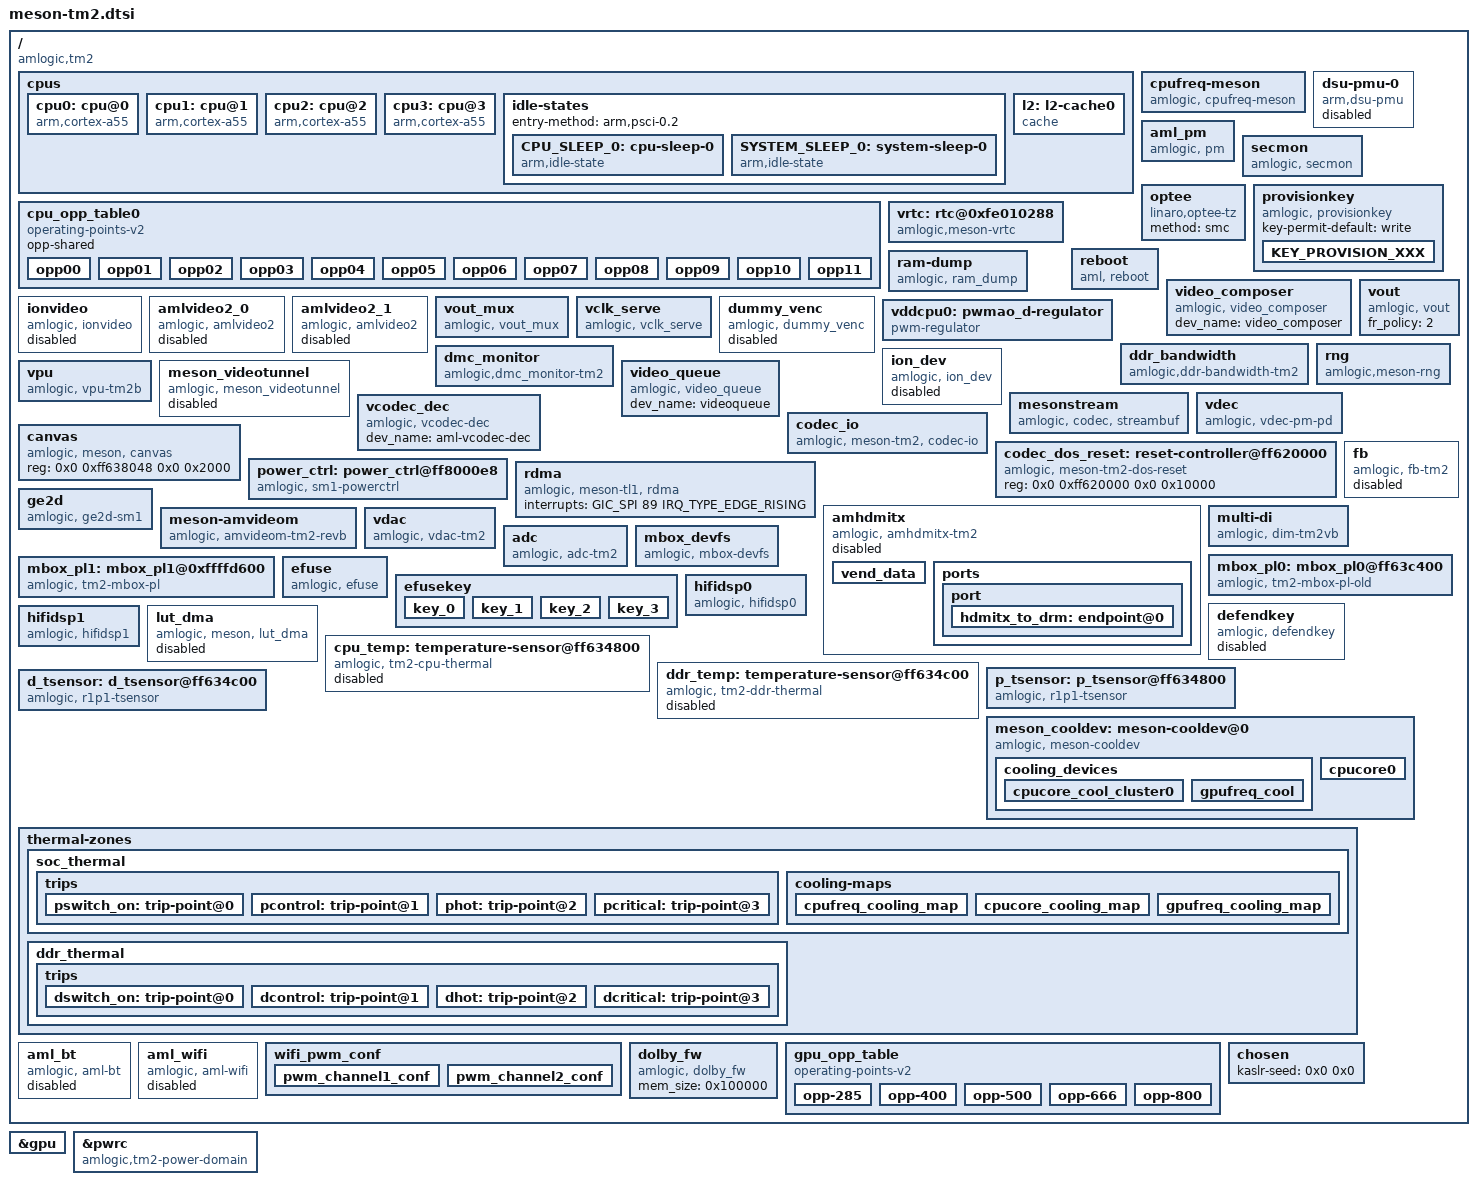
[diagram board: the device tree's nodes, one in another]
// SPDX-License-Identifier: (GPL-2.0+ OR MIT)
/*
 * Copyright (c) 2019 BayLibre, SAS
 * Author: Neil Armstrong <narmstrong@baylibre.com>
 */

#include "meson-tm-common.dtsi"
#include <dt-bindings/clock/tm2-clkc.h>
#include <dt-bindings/power/tm2-pd.h>
#include <dt-bindings/mailbox/tm2-mbox.h>
#include "mesong12a-bifrost.dtsi"
#include <dt-bindings/firmware/amlogic,firmware.h>

/ {
	compatible = "amlogic,tm2";

	cpus {
		#address-cells = <0x2>;
		#size-cells = <0x0>;

		cpu0: cpu@0 {
			device_type = "cpu";
			compatible = "arm,cortex-a55";
			reg = <0x0 0x0>;
			enable-method = "psci";
			//cpu-idle-states = <&CPU_SLEEP_0>;
			next-level-cache = <&l2>;
			clocks = <&clkc CLKID_CPU_CLK>,
				<&clkc CLKID_CPU_CLK_DYN>,
				<&clkc CLKID_SYS_PLL>,
				<&clkc CLKID_DSU_CLK>,
				<&clkc CLKID_DSU_CLK_FINAL>;
			clock-names = "core_clk",
				"low_freq_clk_parent",
				"high_freq_clk_parent",
				"dsu_clk",
				"dsu_pre_parent";
			operating-points-v2 = <&cpu_opp_table0>;
			cpu-supply = <&vddcpu0>;
			voltage-tolerance = <0>;
			clock-latency = <50000>;
			dynamic-power-coefficient = <140>;
			#cooling-cells = <2>;
		};

		cpu1: cpu@1 {
			device_type = "cpu";
			compatible = "arm,cortex-a55";
			reg = <0x0 0x1>;
			enable-method = "psci";
			//cpu-idle-states = <&CPU_SLEEP_0>;
			next-level-cache = <&l2>;
			//clocks = <&clkc CLKID_CPU_CLK>,
			//	<&clkc CLKID_CPU_CLK_DYN>,
			//	<&clkc CLKID_SYS_PLL>,
			//	<&clkc CLKID_DSU_CLK>,
			//	<&clkc CLKID_DSU_CLK_FINAL>;
			//clock-names = "core_clk",
			//	"low_freq_clk_parent",
			//	"high_freq_clk_parent",
			//	"dsu_clk",
			//	"dsu_pre_parent";
			operating-points-v2 = <&cpu_opp_table0>;
			cpu-supply = <&vddcpu0>;
			voltage-tolerance = <0>;
			clock-latency = <50000>;
			dynamic-power-coefficient = <140>;
			#cooling-cells = <2>;
		};

		cpu2: cpu@2 {
			device_type = "cpu";
			compatible = "arm,cortex-a55";
			reg = <0x0 0x2>;
			enable-method = "psci";
			//cpu-idle-states = <&CPU_SLEEP_0>;
			next-level-cache = <&l2>;
			//clocks = <&clkc CLKID_CPU_CLK>,
			//	<&clkc CLKID_CPU_CLK_DYN>,
			//	<&clkc CLKID_SYS_PLL>,
			//	<&clkc CLKID_DSU_CLK>,
			//	<&clkc CLKID_DSU_CLK_FINAL>;
			//clock-names = "core_clk",
			//	"low_freq_clk_parent",
			//	"high_freq_clk_parent",
			//	"dsu_clk",
			//	"dsu_pre_parent";
			operating-points-v2 = <&cpu_opp_table0>;
			cpu-supply = <&vddcpu0>;
			voltage-tolerance = <0>;
			clock-latency = <50000>;
			dynamic-power-coefficient = <140>;
			#cooling-cells = <2>;
		};

		cpu3: cpu@3 {
			device_type = "cpu";
			compatible = "arm,cortex-a55";
			reg = <0x0 0x3>;
			enable-method = "psci";
			//cpu-idle-states = <&CPU_SLEEP_0>;
			next-level-cache = <&l2>;
			//clocks = <&clkc CLKID_CPU_CLK>,
			//	<&clkc CLKID_CPU_CLK_DYN>,
			//	<&clkc CLKID_SYS_PLL>,
			//	<&clkc CLKID_DSU_CLK>,
			//	<&clkc CLKID_DSU_CLK_FINAL>;
			//clock-names = "core_clk",
			//	"low_freq_clk_parent",
			//	"high_freq_clk_parent",
			//	"dsu_clk",
			//	"dsu_pre_parent";
			operating-points-v2 = <&cpu_opp_table0>;
			cpu-supply = <&vddcpu0>;
			voltage-tolerance = <0>;
			clock-latency = <50000>;
			dynamic-power-coefficient = <140>;
			#cooling-cells = <2>;
		};

		idle-states {
			entry-method = "arm,psci-0.2";
			CPU_SLEEP_0: cpu-sleep-0 {
				compatible = "arm,idle-state";
				arm,psci-suspend-param = <0x0010000>;
				local-timer-stop;
				entry-latency-us = <4000>;
				exit-latency-us = <5000>;
				min-residency-us = <10000>;
			};
			SYSTEM_SLEEP_0: system-sleep-0 {
					compatible = "arm,idle-state";
					arm,psci-suspend-param = <0x0000000>;
					entry-latency-us = <0x3fffffff>;
					exit-latency-us = <0x40000000>;
					min-residency-us = <0xffffffff>;
			};
		};

		l2: l2-cache0 {
			compatible = "cache";
		};
	};

	cpu_opp_table0: cpu_opp_table0 {
		compatible = "operating-points-v2";
		opp-shared;

		opp00 {
			opp-hz = /bits/ 64 <100000000>;
			opp-microvolt = <780000>;
		};
		opp01 {
			opp-hz = /bits/ 64 <250000000>;
			opp-microvolt = <780000>;
		};
		opp02 {
			opp-hz = /bits/ 64 <500000000>;
			opp-microvolt = <780000>;
		};
		opp03 {
			opp-hz = /bits/ 64 <667000000>;
			opp-microvolt = <780000>;
		};
		opp04 {
			opp-hz = /bits/ 64 <1000000000>;
			opp-microvolt = <780000>;
		};
		opp05 {
			opp-hz = /bits/ 64 <1200000000>;
			opp-microvolt = <800000>;
		};
		opp06 {
			opp-hz = /bits/ 64 <1404000000>;
			opp-microvolt = <810000>;
		};
		opp07 {
			opp-hz = /bits/ 64 <1500000000>;
			opp-microvolt = <820000>;
		};
		opp08 {
			opp-hz = /bits/ 64 <1608000000>;
			opp-microvolt = <870000>;
		};
		opp09 {
			opp-hz = /bits/ 64 <1704000000>;
			opp-microvolt = <920000>;
		};
		opp10 {
			opp-hz = /bits/ 64 <1800000000>;
			opp-microvolt = <970000>;
		};
		opp11 {
			opp-hz = /bits/ 64 <1908000000>;
			opp-microvolt = <1020000>;
		};
	};

	cpufreq-meson {
		compatible = "amlogic, cpufreq-meson";
		pinctrl-names = "default";
		//pinctrl-0 = <&pwm_ao_d_pins3>;
		status = "okay";
	};

	dsu-pmu-0 {
	compatible = "arm,dsu-pmu";
		status = "disabled";
		cpus = <&cpu0>,<&cpu1>,<&cpu2>,<&cpu3>;
		interrupts = <GIC_SPI 134 IRQ_TYPE_LEVEL_HIGH>;
	};

	aml_pm {
		compatible = "amlogic, pm";
		status = "okay";
		device_name = "aml_pm";
		reg = <0x0 0xff8000a8 0x0 0x4>, /*SYSCTRL_STATUS_REG2*/
			<0x0 0xff80023c 0x0 0x4>; /*SYSCTRL_SEC_STATUS_REG31*/
	};

	secmon {
		compatible = "amlogic, secmon";
		memory-region = <&secmon_reserved>;
		in_base_func = <0x82000020>;
		out_base_func = <0x82000021>;
		inout_size_func = <0x8200002a>;
		reserve_mem_size = <0x00300000>;
	};

	optee {
		compatible = "linaro,optee-tz";
		method = "smc";
	};

	provisionkey {
		compatible = "amlogic, provisionkey";
		status = "okay";
		key-permit-default = "write";
		//new key not need add dts if started with KEY_PROVISION_
		KEY_PROVISION_XXX { };
		//test_my_added_keyname { };
	};//End provisionkey

	vrtc: rtc@0xfe010288 {
		compatible = "amlogic,meson-vrtc";
		reg = <0x0 0xff8000a8 0x0 0x4>;	/*AO_DEBUG_REG2*/
		status = "okay";
		mboxes = <&mbox_pl0 TM2_REE2AO_VRTC>;
	};

	reboot {
		compatible = "aml, reboot";
		sys_reset = <0x84000009>;
		sys_poweroff = <0x84000008>;
		reg = <0x0 0xff80023c 0x0 0x4>; /* SEC_AO_SEC_SD_CFG15 */
		status = "okay";
	};

	ram-dump {
		compatible = "amlogic, ram_dump";
		status = "okay";
		reg = <0x0 0xFF6345E0 0x0 4>;
		reg-names = "SYSCTRL_STICKY_REG6";
		store_device = "data";
	};

	video_composer {
		compatible = "amlogic, video_composer";
		dev_name = "video_composer";
		status = "disabled";
	};

	ionvideo {
		compatible = "amlogic, ionvideo";
		status = "disabled";
	};

	amlvideo2_0 {
		compatible = "amlogic, amlvideo2";
		dev_name = "amlvideo2";
		status = "disabled";
		amlvideo2_id = <0>;
		cma_mode = <1>;
	};

	amlvideo2_1 {
		compatible = "amlogic, amlvideo2";
		dev_name = "amlvideo2";
		status = "disabled";
		amlvideo2_id = <1>;
		cma_mode = <1>;
	};

	vout: vout {
		compatible = "amlogic, vout";
		status = "okay";

		/* fr_policy:
		 *    0: disable
		 *    1: nearby (only for 60->59.94 and 30->29.97)
		 *    2: force (60/50/30/24/59.94/23.97)
		 */
		fr_policy = <2>;
	};

	vout_mux: vout_mux {
		compatible = "amlogic, vout_mux";
		status = "okay";
	};

	vclk_serve: vclk_serve {
		compatible = "amlogic, vclk_serve";
		status = "okay";
		reg = <0x0 0xff63c000 0x0 0x4a0    /* ana reg */
				0x0 0xff63c000 0x0 0x4a0>;    /* clk reg */
	};

	dummy_venc: dummy_venc {
		compatible = "amlogic, dummy_venc";
		status = "disabled";
		clocks = <&clkc CLKID_VCLK2_ENCP
			&clkc CLKID_VCLK2_VENCP0
			&clkc CLKID_VCLK2_VENCP1
			&clkc CLKID_VCLK2_ENCI
			&clkc CLKID_VCLK2_VENCI0
			&clkc CLKID_VCLK2_VENCI1
			&clkc CLKID_VCLK2_ENCL
			&clkc CLKID_VCLK2_VENCL>;
		clock-names = "encp_top_gate",
			"encp_int_gate0",
			"encp_int_gate1",
			"venci_top_gate",
			"enci_int_gate0",
			"enci_int_gate1",
			"encl_top_gate",
			"encl_int_gate";
	};

	vddcpu0: pwmao_d-regulator {
		compatible = "pwm-regulator";
		pwms = <&pwm_AO_cd MESON_PWM_1 1500 0>;
		regulator-name = "vddcpu0";
		regulator-min-microvolt = <690000>;
		regulator-max-microvolt = <1050000>;
		regulator-always-on;
		max-duty-cycle = <1500>;
		/* Voltage Duty-Cycle */
		voltage-table = <1050000 0>,
			<1040000 3>,
			<1030000 6>,
			<1020000 9>,
			<1010000 12>,
			<1000000 14>,
			<990000 17>,
			<980000 20>,
			<970000 23>,
			<960000 26>,
			<950000 29>,
			<940000 31>,
			<930000 34>,
			<920000 37>,
			<910000 40>,
			<900000 43>,
			<890000 45>,
			<880000 48>,
			<870000 51>,
			<860000 54>,
			<850000 56>,
			<840000 59>,
			<830000 62>,
			<820000 65>,
			<810000 68>,
			<800000 70>,
			<790000 73>,
			<780000 76>,
			<770000 79>,
			<760000 81>,
			<750000 84>,
			<740000 87>,
			<730000 89>,
			<720000 92>,
			<710000 95>,
			<700000 98>,
			<690000 100>;
		status = "okay";
	};

	ddr_bandwidth {
		compatible = "amlogic,ddr-bandwidth-tm2";
		status = "okay";
		reg = <0x0 0xff638000 0x0 0x100
		       0x0 0xff638c00 0x0 0x100>;
		interrupts = <GIC_SPI 52 IRQ_TYPE_LEVEL_HIGH>;
		interrupt-names = "ddr_bandwidth";
	};

	dmc_monitor {
		compatible = "amlogic,dmc_monitor-tm2";
		status = "okay";
		reg = <0x0 0xff638000 0x0 0x100>;
		reg_base = <0xff639000>;
		interrupts = <GIC_SPI 52 IRQ_TYPE_LEVEL_HIGH>;
	};

	rng {
		compatible = "amlogic,meson-rng";
		status = "okay";
		#address-cells = <2>;
		#size-cells = <2>;
		reg = <0x0 0xff630218 0x0 0x4>;
		quality = /bits/ 16 <1000>;
	};

	ion_dev: ion_dev {
		status = "disabled";
		compatible = "amlogic, ion_dev";
		memory-region = <&ion_cma_reserved
				&ion_fb_reserved>;
	};

	vpu: vpu {
		compatible = "amlogic, vpu-tm2b";
		status = "okay";
		reg =	<0x0 0xff63c000 0x0 0x200  /* hiu */
			0x0 0xff900000 0x0 0x50000 /* vcbus */
			0x0 0xffd00000 0x0 0x10a0  /* cbus */
			0x0 0xff800000 0x0 0x100>; /* aobus */
		clocks = <&clkc CLKID_VAPB_SEL>,
			<&clkc CLKID_VPU_INTR>,
			<&clkc CLKID_VPU_0>,
			<&clkc CLKID_VPU_1>,
			<&clkc CLKID_VPU>;
		clock-names =	"vapb_clk",
				"vpu_intr_gate",
				"vpu_clk0",
				"vpu_clk1",
				"vpu_clk";
		clk_level = <8>;
		/* 0: 24M       1: 100.0M    2: 166.7M    3: 200.0M    4: 250.0M */
		/* 5: 333.3M    6: 400.0M    7: 500.0M    8: 666.7M */
	};

	meson_videotunnel{
		compatible = "amlogic, meson_videotunnel";
		status = "disabled";
	};

	video_composer {
		compatible = "amlogic, video_composer";
		dev_name = "video_composer";
		status = "okay";
	};

	video_queue {
		compatible = "amlogic, video_queue";
		dev_name = "videoqueue";
		status = "okay";
	};

	mesonstream {
		compatible = "amlogic, codec, streambuf";
		dev_name = "mesonstream";
		status = "okay";
		clocks = <&clkc CLKID_U_PARSER
			&clkc CLKID_DEMUX
			&clkc CLKID_AHB_ARB0
			&clkc CLKID_DOS
			&clkc CLKID_CLK81
			&clkc CLKID_VDEC_MUX
			&clkc CLKID_HCODEC_MUX
			&clkc CLKID_HEVC_MUX
			&clkc CLKID_HEVCF_MUX>;
		clock-names = "parser_top",
			"demux",
			"ahbarb0",
			"vdec",
			"clk_81",
			"clk_vdec_mux",
			"clk_hcodec_mux",
			"clk_hevc_mux",
			"clk_hevcb_mux";
	};

	vdec {
		compatible = "amlogic, vdec-pm-pd";
		dev_name = "vdec.0";
		status = "okay";
		interrupts = <0 3 1
			0 23 1
			0 32 1
			0 43 1
			0 44 1
			0 45 1
			0 74 1>;
		interrupt-names = "vsync",
			"demux",
			"parser",
			"mailbox_0",
			"mailbox_1",
			"mailbox_2",
			"parser_b";
		power-domains = <&pwrc PWRC_TM2_VDEC_ID>,
			<&pwrc PWRC_TM2_HCODEC_ID>,
			<&pwrc PWRC_TM2_HEVC_ID>;
		power-domain-names = "pwrc-vdec",
			"pwrc-hcodec",
			"pwrc-hevc";
	};

	vcodec_dec {
		compatible = "amlogic, vcodec-dec";
		dev_name = "aml-vcodec-dec";
		status = "okay";
	};

	canvas: canvas {
		compatible = "amlogic, meson, canvas";
		status = "okay";
		reg = <0x0 0xff638048 0x0 0x2000>;
	};

	codec_io: codec_io {
		compatible = "amlogic, meson-tm2, codec-io";
		status = "okay";
		#address-cells=<2>;
		#size-cells=<2>;
		ranges;
		reg =	<0x0 0xffd00000 0x0 0x100000>,
			<0x0 0xff620000 0x0 0x10000>,
			<0x0 0xff63c000 0x0 0x2000>,
			<0x0 0xff800000 0x0 0x10000>,
			<0x0 0xff900000 0x0 0x40000>,
			<0x0 0xff638000 0x0 0x2000>,
			<0x0 0xff630000 0x0 0x2000>;
		reg-names = "cbus",
			    "dosbus",
			    "hiubus",
			    "aobus",
			    "vcbus",
			    "dmcbus",
			    "efusebus";
	};

	codec_dos_reset: reset-controller@ff620000 {
		compatible = "amlogic, meson-tm2-dos-reset";
		status = "okay";
		reg = <0x0 0xff620000 0x0 0x10000>;
		#reset-cells = <1>;
	};

	power_ctrl: power_ctrl@ff8000e8 {
		compatible = "amlogic, sm1-powerctrl";
		reg = <0x0 0xff8000e8 0x0 0x10>,
		<0x0 0xff63c100 0x0 0x10>;
	};

	rdma {
		compatible = "amlogic, meson-tl1, rdma";
		status = "okay";
		interrupts = <GIC_SPI 89 IRQ_TYPE_EDGE_RISING>;
		interrupt-names = "rdma";
	};

	fb: fb {
		compatible = "amlogic, fb-tm2";
		memory-region = <&logo_reserved>;
		status = "disabled";
		interrupts = <GIC_SPI 3 IRQ_TYPE_EDGE_RISING
			GIC_SPI 56 IRQ_TYPE_EDGE_RISING
			GIC_SPI 89 IRQ_TYPE_EDGE_RISING>;
		interrupt-names = "viu-vsync", "viu2-vsync", "rdma";
		/* uboot logo,fb0/fb1 memory size,if afbcd fb0=0x01851000*/
		display_mode_default = "1080p60hz";
		scale_mode = <1>;
		/** 0:VPU free scale 1:OSD free scale 2:OSD super scale */
		display_size_default = <1920 1080 1920 2160 32>;
		/*1920*1080*4*3 = 0x17BB000*/
		clocks = <&clkc CLKID_VPU_CLKC_MUX>;
		clock-names = "vpu_clkc";
	};

	amhdmitx: amhdmitx{
		compatible = "amlogic, amhdmitx-tm2";
		dev_name = "amhdmitx";
		status = "disabled";
		vend-data = <&vend_data>;
		pinctrl-names="default", "hdmitx_i2c";
		pinctrl-0=<&hdmitx_hpd &hdmitx_ddc>;
		pinctrl-1=<&hdmitx_hpd_gpio>;
		hdmitx-gpios-hpd = <&gpio GPIOH_16 0>;
		hdmitx-gpios-scl = <&gpio GPIOH_23 0>;
		hdmitx-gpios-sda = <&gpio GPIOH_24 0>;
		clocks = <&clkc CLKID_VCLK2_ENCI
			&clkc CLKID_VCLK2_VENCI0
			&clkc CLKID_VCLK2_VENCI1
			&clkc CLKID_VAPB_SEL
			&clkc CLKID_VPU
			&clkc CLKID_HDMIRX_AXI_GATE>;
		clock-names = "venci_top_gate",
			"venci_0_gate",
			"venci_1_gate",
			"hdmi_vapb_clk",
			"hdmi_vpu_clk",
			"cts_hdmi_axi_clk";
		interrupts = <0 7 IRQ_TYPE_LEVEL_HIGH
			0 3 IRQ_TYPE_EDGE_RISING>;
		interrupt-names = "hdmitx_hpd", "viu1_vsync";
		/* HPD, 57 + 32 = 89; CEC, 151 + 32 = 183*/
		/* 0:M8B   1:GXBB 2:GXTVBB 3:GXL  4:GXM
		 * 5:TXL   6:TXLX 7:AXG    8:GXLX 9:TXHD
		 * 10:G12A 11:G12B 12:SM1  13:TM2
		 */
		ic_type = <13>;
		reg =	<0x0 0xffd00000 0x0 0x100000>,
			<0x0 0xff900000 0x0 0x40000>,
			<0x0 0xff63c000 0x0 0x2000>,
			<0x0 0xff678000 0x0 0x8000>,
			<0x0 0xff670000 0x0 0x8000>,
			<0x0 0xffe01000 0x0 0x1000>;
		reg-names = "cbus",
			    "vcbus",
			    "hiubus",
			    "hdmitx_sec",
			    "hdmitx",
			    "esm";
		vend_data: vend_data{ /* Should modified by Customer */
			vendor_name = "Amlogic"; /* Max Chars: 8 */
			product_desc = "MBox Meson Ref"; /* Max Chars: 16 */
			/* standards.ieee.org/develop/regauth/oui/oui.txt */
			vendor_id = <0x000000>;
		};

		ports {
			port {
				#address-cells = <1>;
				#size-cells = <0>;
				hdmitx_to_drm: endpoint@0 {
					reg = <0>;
					remote-endpoint = <0>;
				};
			};
		};
	};

	ge2d {
		compatible = "amlogic, ge2d-sm1";
		status = "okay";
		interrupts = <GIC_SPI 146 IRQ_TYPE_EDGE_RISING>;
		interrupt-names = "ge2d";
		clocks = <&clkc CLKID_VAPB_SEL>,
			<&clkc CLKID_G2D>,
			<&clkc CLKID_VAPB>;
		clock-names = "clk_vapb_0",
			"clk_ge2d",
			"clk_ge2d_gate";
		reg = <0x0 0xff940000 0x0 0x10000>;
		power-domains = <&pwrc PWRC_TM2_GE2D_ID>;
		power-domain-names = "ge2d";
	};

	multi-di {
		compatible = "amlogic, dim-tm2vb";
		status = "okay";
		/* 0:use reserved; 1:use cma; 2:use cma as reserved */
		flag_cma = <4>;
		//memory-region = <&di_reserved>;
		memory-region = <&di_cma_reserved>;
		interrupts = <0 46 1
				0 40 1>;
		interrupt-names = "pre_irq", "post_irq";
		clocks = <&clkc CLKID_VPU_CLKB
			&clkc CLKID_VPU>;
		clock-names = "vpu_clkb",
			"vpu_mux";
		clock-range = <334 667>;
		/* buffer-size = <3621952>;(yuv422 8bit) */
		buffer-size = <4074560>;/*yuv422 fullpack*/
		/* reserve-iomap = "true"; */
		/* if enable nr10bit, set nr10bit-support to 1 */
		post-wr-support = <1>;
		nr10bit-support = <1>;
		nrds-enable = <1>;
		pps-enable = <1>;
	};

	meson-amvideom {
		compatible = "amlogic, amvideom-tm2-revb";
		dev_name = "amvideom";
		status = "okay";
		interrupts = <0 3 1>;
		interrupt-names = "vsync";
	};

	vdac: vdac {
		compatible = "amlogic, vdac-tm2";
		status = "okay";
	};

	adc: adc {
		compatible = "amlogic, adc-tm2";
		status = "okay";
		reg = <0x0 0xff654000 0x0 0x2000/* afe reg base */
			0x0 0xff63c000 0x0 0x2000/* hiu base */
			>;
	};

	mbox_pl0: mbox_pl0@ff63c400 {
		status = "okay";
		compatible = "amlogic, tm2-mbox-pl-old";
		reg = <0x0 0xfffdf200 0x0 0x200>,   // aocpu tx buf low
		      <0x0 0xfffdf000 0x0 0x200>,   // aocpu rx buf low
		      <0x0 0xff63c434 0x0 0x4>,     // aocpu tx set addr low
		      <0x0 0xff63c418 0x0 0x4>,     // aocpu rx clr addr low
		      <0x0 0xff63c414 0x0 0x4>,     // aocpu rx sts addr low
		      <0x0 0xfffdf600 0x0 0x200>,   // aocpu tx buf high
		      <0x0 0xfffdf400 0x0 0x200>,   // aocpu rx buf high
		      <0x0 0xff63c440 0x0 0x4>,     // aocpu tx set addr high
		      <0x0 0xff63c424 0x0 0x4>,     // aocpu rx clr addr high
		      <0x0 0xff63c420 0x0 0x4>;     // aocpu rx sts addr high
		interrupts = <GIC_SPI 209 IRQ_TYPE_EDGE_RISING>,  // aocpu rx irq low
			     <GIC_SPI 210 IRQ_TYPE_EDGE_RISING>;  // aocpu rx irq high
		mbox-tx = "tx", "tx";
		mbox-nums = <TM2_MBOX_PL0_NUMS>;
		mboxids = <TM2_MBOX_REE2AO_LOW>,
			  <TM2_MBOX_REE2AO_HIGH>;
		#mbox-cells = <1>;
	};

	mbox_pl1: mbox_pl1@0xffffd600 {
		status = "okay";
		compatible = "amlogic, tm2-mbox-pl";
		reg = <0x0 0xfffdca00 0x0 0x200>,    // dspa tx buf
		      <0x0 0xff680154 0x0 0x4>,      // dspa tx set addr
		      <0x0 0xff680194 0x0 0x4>,      // dspa tx clr addr
		      <0x0 0xff6801d4 0x0 0x4>,      // dspa tx sts addr
		      <0x0 0xfffdc800 0x0 0x200>,    // dspa rx buf
		      <0x0 0xff680150 0x0 0x4>,      // dspa rx set addr
		      <0x0 0xff680190 0x0 0x4>,      // dspa rx clr addr
		      <0x0 0xff6801d0 0x0 0x4>,      // dspa rx sts addr
		      <0x0 0xfffdce00 0x0 0x200>,    // dspb tx buf
		      <0x0 0xff690154 0x0 0x4>,      // dspb tx set addr
		      <0x0 0xff690194 0x0 0x4>,      // dspb tx clr addr
		      <0x0 0xff6901d4 0x0 0x4>,      // dspb tx sts addr
		      <0x0 0xfffdcc00 0x0 0x200>,    // dspb rx buf
		      <0x0 0xff690150 0x0 0x4>,      // dspb rx set addr
		      <0x0 0xff690190 0x0 0x4>,      // dspb rx clr addr
		      <0x0 0xff6901d0 0x0 0x4>;      // dspb rx sts addr
		interrupts = <GIC_SPI 244 IRQ_TYPE_EDGE_RISING>,  // dspa send irq
			     <GIC_SPI 242 IRQ_TYPE_EDGE_RISING>,  // dspa rev irq
			     <GIC_SPI 248 IRQ_TYPE_EDGE_RISING>,  // dspb send irq
			     <GIC_SPI 246 IRQ_TYPE_EDGE_RISING>;  // dspb rev irq
		mbox-tx = "tx", "rx", "tx", "rx";
		mbox-nums = <TM2_MBOX_PL1_NUMS>;
		mboxids = <TM2_MBOX_REE2DSPA>,
			  <TM2_MBOX_DSPA2REE>,
			  <TM2_MBOX_REE2DSPB>,
			  <TM2_MBOX_DSPB2REE>;
		#mbox-cells = <1>;
	};

	mbox_devfs {
		status = "okay";
		compatible = "amlogic, mbox-devfs";
		mbox-nums = <5>;
		mbox-names = "ree2aocpu",
			     "dsp_dev",
			     "dsp2ree",
			     "dspb_dev",
			     "dspb2ree";
		mboxes = <&mbox_pl0 TM2_REE2AO_DEV>,
			 <&mbox_pl1 TM2_REE2DSPA_DEV>,
			 <&mbox_pl1 TM2_DSPA2REE_DEV>,
			 <&mbox_pl1 TM2_REE2DSPB_DEV>,
			 <&mbox_pl1 TM2_DSPB2REE_DEV>;
		mbox-dests = <MAILBOX_AOCPU>,
			     <MAILBOX_DSP>,
			     <MAILBOX_DSP>,
			     <MAILBOX_DSP>,
			     <MAILBOX_DSP>;
	};

	optee {
		compatible = "linaro,optee-tz";
		method = "smc";
	};

	provisionkey {
		compatible = "amlogic, provisionkey";
		status = "okay";
		key-permit-default = "write";
		//new key not need add dts if started with KEY_PROVISION_
		KEY_PROVISION_XXX { };
		//test_my_added_keyname { };
	};//End provisionkey

	efuse: efuse {
		compatible = "amlogic, efuse";
		read_cmd = <0x82000030>;
		write_cmd = <0x82000031>;
		get_max_cmd = <0x82000033>;
		mem_in_base_cmd = <0x82000020>;
		mem_out_base_cmd = <0x82000021>;
		reg=<0x0 0xff800228 0x0 0x4>;
		secureboot_mask = <0x00000010>;
		key = <&efusekey>;
		clocks = <&clkc CLKID_EFUSE>;
		clock-names = "efuse_clk";
		status = "okay";
	};

	efusekey: efusekey {
		keynum = <4>;
		key0 = <&key_0>;
		key1 = <&key_1>;
		key2 = <&key_2>;
		key3 = <&key_3>;

		key_0: key_0 {
			keyname = "mac";
			offset = <0>;
			size = <6>;
		};
		key_1: key_1 {
			keyname = "mac_bt";
			offset = <6>;
			size = <6>;
		};
		key_2: key_2 {
			keyname = "mac_wifi";
			offset = <12>;
			size = <6>;
		};
		key_3: key_3 {
			keyname = "usid";
			offset = <18>;
			size = <16>;
		};
	};

	defendkey: defendkey {
		compatible = "amlogic, defendkey";
		reg=<0x0 0xff800228 0x0 0x4>;
		memory-region = <&defendkey_reserved>;
		mem_size = <0x100000>;
		status = "disabled";
	};

	hifidsp0: hifidsp0 {
		compatible = "amlogic, hifidsp0";
		status = "okay";
		startup-position = /bits/ 8 <PURE_DDR>; /*host dsp start mode : DDR*/
		memory-region = <&dsp_fw_reserved0>;
		reg-names = "base-reg",
			    "ddrfw-region";
		reg = <0x0 0xff680000 0x0 0x114>, /*host base reg address*/
		      <0x0 0x0 0x0 0xa00000>; /*host ddrfw region [offset size]*/
		clocks = <&clkc CLKID_DSPA_MUX>;
		clock-names = "dspa_clk";
		mbox-names = "init_dsp";
		mboxes = <&mbox_pl0 TM2_REE2AO_HIFI4DSPA>;
		power-domains = <&pwrc  PWRC_TM2_DSPA_ID>;
		clkfreq-khz = <400000>;
	};

	hifidsp1: hifidsp1 {
		compatible = "amlogic, hifidsp1";
		status = "okay";
		startup-position = /bits/ 8 <PURE_DDR>; /*host dsp start mode : DDR*/
		memory-region = <&dsp_fw_reserved1>;
		reg-names = "base-reg",
			    "ddrfw-region";
		reg = <0x0 0xff690000 0x0 0x114>, /*host base reg address*/
		      <0x0 0x0 0x0 0x600000>; /*host ddrfw region [offset size]*/
		clocks = <&clkc CLKID_DSPB_MUX>;
		clock-names = "dspb_clk";
		mbox-names = "init_dsp";
		mboxes = <&mbox_pl0 TM2_REE2AO_HIFI4DSPB>;
		power-domains = <&pwrc  PWRC_TM2_DSPB_ID>;
		clkfreq-khz = <400000>;
	};

	lut_dma:lut_dma {
		compatible = "amlogic, meson, lut_dma";
		status = "disabled";
	};

	cpu_temp: temperature-sensor@ff634800 {
		compatible = "amlogic, tm2-cpu-thermal",
			     "amlogic, tm2-thermal";
		reg = <0x0 0xff634800 0x0 0x50>,
			<0x0 0xff800268 0x0 0x4>;
		interrupts = <0 35 0>;
		clocks = <&clkc CLKID_TS>; /* CLKID_TS_COMP>;*/
		#thermal-sensor-cells = <1>;
		status = "disabled";
	};

	ddr_temp: temperature-sensor@ff634c00 {
		compatible = "amlogic, tm2-ddr-thermal",
			     "amlogic, tm2-thermal";
		reg = <0x0 0xff634c00 0x0 0x50>,
			<0x0 0xff800230 0x0 0x4>;
		interrupts = <0 36 0>;
		clocks = <&clkc CLKID_TS>; /* CLKID_TS_COMP>;*/
		#thermal-sensor-cells = <1>;
		status = "disabled";
	};

	p_tsensor: p_tsensor@ff634800 {
		compatible = "amlogic, r1p1-tsensor";
		status = "okay";
		reg = <0x0 0xff634800 0x0 0x50>,
			<0x0 0xff800268 0x0 0x4>;
		cal_type = <0x1>;
		cal_coeff = <324 424 3159 9411>;
		rtemp = <110000>;
		interrupts = <GIC_SPI 35 IRQ_TYPE_LEVEL_HIGH>;
		clocks = <&clkc CLKID_TS>; /* CLKID_TS_COMP>;*/
		clock-names = "ts_comp";
		#thermal-sensor-cells = <1>;
	};

	d_tsensor: d_tsensor@ff634c00 {
		compatible = "amlogic, r1p1-tsensor";
		status = "okay";
		reg = <0x0 0xff634c00 0x0 0x50>,
			<0x0 0xff800230 0x0 0x4>;
		cal_type = <0x1>;
		cal_coeff = <324 424 3159 9411>;
		rtemp = <110000>;
		interrupts = <GIC_SPI 36 IRQ_TYPE_LEVEL_HIGH>;
		clocks = <&clkc CLKID_TS>; /* CLKID_TS_COMP>;*/
		clock-names = "ts_comp";
		#thermal-sensor-cells = <1>;
	};
	meson_cooldev: meson-cooldev@0 {
		status = "okay";
		compatible = "amlogic, meson-cooldev";
		cooling_devices {
			cpucore_cool_cluster0 {
				cluster_id = <0>;
				device_type = "cpucore";
				node_name = "cpucore0";
			};
			gpufreq_cool {
				dyn_coeff = <160>;
				device_type = "gpufreq";
				node_name = "bifrost";
			};
		};
		cpucore0:cpucore0 {
			#cooling-cells = <2>;
		};
	};

	thermal-zones {
		soc_thermal: soc_thermal {
			polling-delay = <1000>;
			polling-delay-passive = <100>;
			sustainable-power = <1230>;
			thermal-sensors = <&p_tsensor 0>;
			trips {
				pswitch_on: trip-point@0 {
					temperature = <60000>;
					hysteresis = <5000>;
					type = "passive";
				};
				pcontrol: trip-point@1 {
					temperature = <75000>;
					hysteresis = <5000>;
					type = "passive";
				};
				phot: trip-point@2 {
					temperature = <85000>;
					hysteresis = <5000>;
					type = "hot";
				};
				pcritical: trip-point@3 {
					temperature = <105000>;
					hysteresis = <1000>;
					type = "critical";
				};
			};
			cooling-maps {
				cpufreq_cooling_map {
					trip = <&pcontrol>;
					cooling-device = <&cpu0 0 7>;
					contribution = <1024>;
				};
				cpucore_cooling_map {
					trip = <&pcontrol>;
					cooling-device = <&cpucore0 0 4>;
					contribution = <1024>;
				};
				gpufreq_cooling_map {
					trip = <&pcontrol>;
					cooling-device = <&gpu 0 2>;
					contribution = <1024>;
				};
			};
		};
		ddr_thermal: ddr_thermal {
			polling-delay = <2000>;
			polling-delay-passive = <1000>;
			sustainable-power = <1230>;
			thermal-sensors = <&d_tsensor 1>;
			trips {
				dswitch_on: trip-point@0 {
					temperature = <60000>;
					hysteresis = <5000>;
					type = "passive";
				};
				dcontrol: trip-point@1 {
					temperature = <75000>;
					hysteresis = <5000>;
					type = "passive";
				};
				dhot: trip-point@2 {
					temperature = <85000>;
					hysteresis = <5000>;
					type = "hot";
				};
				dcritical: trip-point@3 {
					temperature = <105000>;
					hysteresis = <1000>;
					type = "critical";
				};
			};
		};
	}; /*thermal zone end*/

	aml_bt: aml_bt {
		compatible = "amlogic, aml-bt";
		status = "disabled";
	};

	aml_wifi: aml_wifi {
		compatible = "amlogic, aml-wifi";
		status = "disabled";
		irq_trigger_type = "IRQF_TRIGGER_LOW";
		wifi_static_buf = <1>;
		/* dhd_static_buf; */ /* if use bcm wifi, config dhd_static_buf */
		//pinctrl-0 = <&pwm_e_pins>;
		//pinctrl-names = "default";
		pwm_config = <&wifi_pwm_conf>;
	};

	wifi_pwm_conf:wifi_pwm_conf{
		pwm_channel1_conf {
			pwms = <&pwm_ab MESON_PWM_1 30550 0>;
			duty-cycle = <15270>;
			times = <8>;
		};
		pwm_channel2_conf {
			pwms = <&pwm_ab MESON_PWM_3 30500 0>;
			duty-cycle = <15250>;
			times = <12>;
		};
	};
	dolby_fw: dolby_fw {
		compatible = "amlogic, dolby_fw";
		mem_size = <0x100000>;
		status = "okay";
	};

	gpu_opp_table: gpu_opp_table {
		compatible = "operating-points-v2";

		opp-285 {
			opp-hz = /bits/ 64 <285714281>;
			opp-microvolt = <1150>;
		};
		opp-400 {
			opp-hz = /bits/ 64 <400000000>;
			opp-microvolt = <1150>;
		};
		opp-500 {
			opp-hz = /bits/ 64 <500000000>;
			opp-microvolt = <1150>;
		};
		opp-666 {
			opp-hz = /bits/ 64 <666666666>;
			opp-microvolt = <1150>;
		};
		opp-800 {
			opp-hz = /bits/ 64 <800000000>;
			opp-microvolt = <1150>;
		};
	};

	chosen {
		kaslr-seed = <0x0 0x0>;
	};
};

&gpu{
	status = "okay";
	clocks = <&clkc CLKID_MALI>;
	clock-names = "gpu_mux";

	/*
	 * Mali clocking is provided by two identical clock paths
	 * MALI_0 and MALI_1 muxed to a single clock by a glitch
	 * free mux to safely change frequency while running.
	 */
	assigned-clocks = <&clkc CLKID_MALI_0_SEL>,
			  <&clkc CLKID_MALI_0>,
			  <&clkc CLKID_MALI>; /* Glitch free mux */
	assigned-clock-parents = <&clkc CLKID_FCLK_DIV4>,
				 <0>, /* Do Nothing */
				 <&clkc CLKID_MALI_0>;
	assigned-clock-rates = <0>, /* Do Nothing */
				   <500000000>,
				   <0>; /* Do Nothing */

	tbl =  <&dvfs285_cfg
		&dvfs400_cfg
		&dvfs500_cfg
		&dvfs666_cfg
		&dvfs800_cfg
		&dvfs800_cfg>;
};

&pwrc {
	compatible = "amlogic,tm2-power-domain";
};
